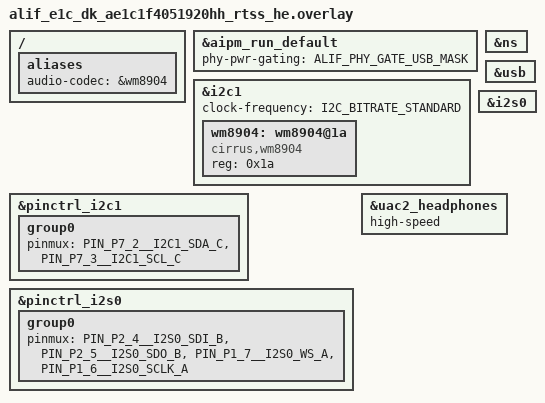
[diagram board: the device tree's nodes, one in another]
/*
 * Copyright (c) 2025 Alif Semiconductor.
 * SPDX-License-Identifier: Apache-2.0 */
#include "../app.overlay"

#include <dt-bindings/misc/alif_aipm_common.h>

&aipm_run_default {
	phy-pwr-gating = <ALIF_PHY_GATE_USB_MASK>;
};

ns: &ns {
	status = "okay";
};

zephyr_udc0: &usb {
	status = "okay";
};

// &zephyr_udc0 {
// 	cdc_acm_uart0 {
// 		compatible = "zephyr,cdc-acm-uart";
// 		label = "Zephyr USB CDC-ACM";
// 	};
// };

&i2c1 {
	clock-frequency = <I2C_BITRATE_STANDARD>;
	status = "okay";

	wm8904: wm8904@1a {
		compatible = "cirrus,wm8904";
		reg = <0x1a>;
		status = "okay";
	};
};

i2s_tx: &i2s0 {
#if 0
	/delete-property/ clock-frequency;
	/delete-property/ driver-instance;
	compatible = "alif,i2s-sync";
	bit-depth = <16>;
	sample-rate = <48000>;
#endif
	status = "okay";
};

&pinctrl_i2c1 {
	group0 {
		pinmux = <PIN_P7_2__I2C1_SDA_C>,
			 <PIN_P7_3__I2C1_SCL_C>;
	};
};

&pinctrl_i2s0 {
	group0 {
		pinmux = <PIN_P2_4__I2S0_SDI_B>,
			 <PIN_P2_5__I2S0_SDO_B>,
			 <PIN_P1_7__I2S0_WS_A>,
			 <PIN_P1_6__I2S0_SCLK_A>;
	};
};

&uac2_headphones {
	high-speed;
};

/* Listen-only: SOF-synchronous ISO OUT. Linux will send audio without waiting
 * for an explicit feedback IN endpoint (EP3).
 */
//&uac_aclk {
//	sof-synchronized;
//};

/ {
	aliases {
		audio-codec = &wm8904;
	};
};
